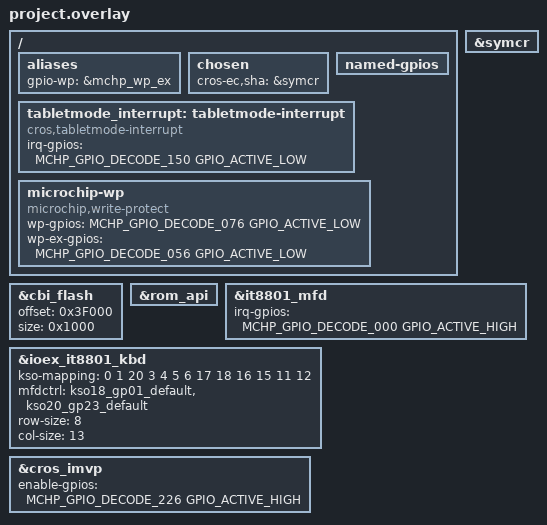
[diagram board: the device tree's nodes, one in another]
/* Copyright 2024 The ChromiumOS Authors
 * Use of this source code is governed by a BSD-style license that can be
 * found in the LICENSE file.
 */

#include "include/board.h"

#include <cros/cbi_flash.dtsi>
#include <cros/integrated_fwid.dtsi>

#include "adc.dtsi"
#include "fan.dtsi"
#include "gpio.dtsi"
#include "i2c.dts"
#include "imvp.dtsi"
#include "keyboard.dtsi"
#include "vci.dtsi"
#include "../battery.dtsi"
#include "../gsc_board.dtsi"
#include "../i2c.dtsi"
#include "../ioex_gpio.dtsi"
#include "../interrupts.dtsi"
#include "../runtime_pd.dtsi"
#include "../power_signals.dtsi"
#include "../temp_sensor.dts"
#include "../runtime_usbc.dtsi"
#include "../led_pins.dtsi"
#include "../led_policy.dtsi"

&cbi_flash {
	offset = <0x3F000>;
	size = <0x1000>;
};

/ {
	aliases {
		gpio-wp = &mchp_wp_ex;
	};
	chosen {
		cros-ec,sha = &symcr;
	};
	named-gpios {
		/delete-node/  ec-jtag-tms;
	};

	tabletmode_interrupt: tabletmode-interrupt {
		compatible = "cros,tabletmode-interrupt";
		irq-gpios = <MCHP_GPIO_DECODE_150 GPIO_ACTIVE_LOW>;
	};

	microchip-wp {
		compatible ="microchip,write-protect";
		wp-gpios = <MCHP_GPIO_DECODE_076 GPIO_ACTIVE_LOW>;
		wp-ex-gpios = <MCHP_GPIO_DECODE_056 GPIO_ACTIVE_LOW>;
	};
};

&symcr {
	status = "okay";
};

&rom_api {
	status = "okay";
};

&it8801_mfd {
	irq-gpios = <MCHP_GPIO_DECODE_000 GPIO_ACTIVE_HIGH>;
};

&ioex_it8801_kbd {
          status="okay";
          kso-mapping = <0 1 20 3 4 5 6 17 18 16 15 11 12>;
          mfdctrl = <&kso18_gp01_default &kso20_gp23_default>;
          row-size = <8>;
          col-size = <13>;
};

&cros_imvp{
		enable-gpios = <MCHP_GPIO_DECODE_226 GPIO_ACTIVE_HIGH>;
};
